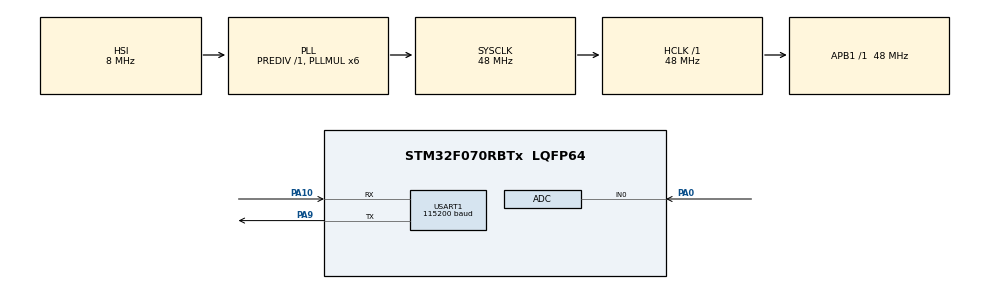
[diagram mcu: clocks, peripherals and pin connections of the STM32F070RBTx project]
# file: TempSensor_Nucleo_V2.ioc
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ADC.Resolution=ADC_RESOLUTION_10B
ADC.SamplingTime=ADC_SAMPLETIME_13CYCLES_5
Mcu.Family=STM32F0
Mcu.Name=STM32F070RBTx
Mcu.Package=LQFP64
NVIC.USART1_IRQn=true\:0\:0\:false\:false\:true\:true\:true\:true
PA0.Mode=IN0
PA0.Signal=ADC_IN0
PA10.Mode=Asynchronous
PA10.Signal=USART1_RX
PA9.Mode=Asynchronous
PA9.Signal=USART1_TX
PF0-OSC_IN.Mode=HSE-External-Oscillator
PF0-OSC_IN.Signal=RCC_OSC_IN
PF1-OSC_OUT.Mode=HSE-External-Oscillator
PF1-OSC_OUT.Signal=RCC_OSC_OUT
ProjectManager.HeapSize=0x200
ProjectManager.StackSize=0x400
ProjectManager.TargetToolchain=STM32CubeIDE
RCC.AHBFreq_Value=48000000
RCC.APB1Freq_Value=48000000
RCC.APB1TimFreq_Value=48000000
RCC.HCLKFreq_Value=48000000
RCC.PLLMUL=RCC_PLL_MUL6
RCC.SYSCLKFreq_VALUE=48000000
RCC.SYSCLKSource=RCC_SYSCLKSOURCE_PLLCLK
USART1.BaudRate=115200
USART1.VirtualMode-Asynchronous=VM_ASYNC
board=NUCLEO-F070RB

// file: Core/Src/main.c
/* USER CODE BEGIN Header */
/**
  ******************************************************************************
  * @file           : main.c
  * @brief          : Main program body
  ******************************************************************************
  * @attention
  *
  * Copyright (c) 2023 STMicroelectronics.
  * All rights reserved.
  *
  * This software is licensed under terms that can be found in the LICENSE file
  * in the root directory of this software component.
  * If no LICENSE file comes with this software, it is provided AS-IS.
  *
  ******************************************************************************
  */
/* USER CODE END Header */
#include "main.h"

/* USER CODE BEGIN Includes */ // CUSTOM CODE

#include <string.h>
#include <stdio.h>

/* USER CODE END Includes */

ADC_HandleTypeDef hadc;

UART_HandleTypeDef huart1;

void SystemClock_Config(void);
static void MX_GPIO_Init(void);
static void MX_ADC_Init(void);
static void MX_USART1_UART_Init(void);

/* USER CODE BEGIN 0 */
uint32_t adcval;
float temp;
char temp_str[20];
uint8_t msg[38] = "Hello World\n";

/* USER CODE END 0 */

int main(void)
{

  /* MCU Configuration--------------------------------------------------------*/

  /* Reset of all peripherals, Initializes the Flash interface and the Systick. */
  HAL_Init();

  /* Configure the system clock */
  SystemClock_Config();

  /* Initialize all configured peripherals */
  MX_GPIO_Init();
  MX_ADC_Init();
  MX_USART1_UART_Init();

  /* Infinite loop */
  while (1)
  {

    /* USER CODE BEGIN 3 */ // CUSTOM CODE
	  HAL_UART_Transmit(&huart1, msg, 38, 10);
	  HAL_ADC_Start(&hadc);
	  if (HAL_ADC_PollForConversion(&hadc, 5) == HAL_OK)
	  {
		  adcval = HAL_ADC_GetValue(&hadc);
		  temp = (adcval*330.0)/1023.0; // voltage = (adcval*supply_voltage) / (adc resolution)
	  	  	  	  	  	  	  	  // 10 bits adc resolution means 2^10 = 1023

		  snprintf(temp_str, sizeof(temp_str), "Temperature: %.2f C\r\n", temp); // @suppress("Float formatting support")
		  HAL_UART_Transmit(&huart1, (uint8_t *)temp_str, strlen(temp_str), HAL_MAX_DELAY);
		  HAL_Delay(1000);

	  }

  }
  /* USER CODE END 3 */
}

void SystemClock_Config(void)
{
  RCC_OscInitTypeDef RCC_OscInitStruct = {0};
  RCC_ClkInitTypeDef RCC_ClkInitStruct = {0};
  RCC_PeriphCLKInitTypeDef PeriphClkInit = {0};

  /** Initializes the RCC Oscillators according to the specified parameters
  * in the RCC_OscInitTypeDef structure.
  */
  RCC_OscInitStruct.OscillatorType = RCC_OSCILLATORTYPE_HSI|RCC_OSCILLATORTYPE_HSI14;
  RCC_OscInitStruct.HSIState = RCC_HSI_ON;
  RCC_OscInitStruct.HSI14State = RCC_HSI14_ON;
  RCC_OscInitStruct.HSICalibrationValue = RCC_HSICALIBRATION_DEFAULT;
  RCC_OscInitStruct.HSI14CalibrationValue = 16;
  RCC_OscInitStruct.PLL.PLLState = RCC_PLL_ON;
  RCC_OscInitStruct.PLL.PLLSource = RCC_PLLSOURCE_HSI;
  RCC_OscInitStruct.PLL.PLLMUL = RCC_PLL_MUL6;
  RCC_OscInitStruct.PLL.PREDIV = RCC_PREDIV_DIV1;
  if (HAL_RCC_OscConfig(&RCC_OscInitStruct) != HAL_OK)
  {
    Error_Handler();
  }

  /** Initializes the CPU, AHB and APB buses clocks
  */
  RCC_ClkInitStruct.ClockType = RCC_CLOCKTYPE_HCLK|RCC_CLOCKTYPE_SYSCLK
                              |RCC_CLOCKTYPE_PCLK1;
  RCC_ClkInitStruct.SYSCLKSource = RCC_SYSCLKSOURCE_PLLCLK;
  RCC_ClkInitStruct.AHBCLKDivider = RCC_SYSCLK_DIV1;
  RCC_ClkInitStruct.APB1CLKDivider = RCC_HCLK_DIV1;

  if (HAL_RCC_ClockConfig(&RCC_ClkInitStruct, FLASH_LATENCY_1) != HAL_OK)
  {
    Error_Handler();
  }
  PeriphClkInit.PeriphClockSelection = RCC_PERIPHCLK_USART1;
  PeriphClkInit.Usart1ClockSelection = RCC_USART1CLKSOURCE_PCLK1;
  if (HAL_RCCEx_PeriphCLKConfig(&PeriphClkInit) != HAL_OK)
  {
    Error_Handler();
  }
}

static void MX_ADC_Init(void)
{

  ADC_ChannelConfTypeDef sConfig = {0};

  /** Configure the global features of the ADC (Clock, Resolution, Data Alignment and number of conversion)
  */
  hadc.Instance = ADC1;
  hadc.Init.ClockPrescaler = ADC_CLOCK_ASYNC_DIV1;
  hadc.Init.Resolution = ADC_RESOLUTION_10B;
  hadc.Init.DataAlign = ADC_DATAALIGN_RIGHT;
  hadc.Init.ScanConvMode = ADC_SCAN_DIRECTION_FORWARD;
  hadc.Init.EOCSelection = ADC_EOC_SINGLE_CONV;
  hadc.Init.LowPowerAutoWait = DISABLE;
  hadc.Init.LowPowerAutoPowerOff = DISABLE;
  hadc.Init.ContinuousConvMode = DISABLE;
  hadc.Init.DiscontinuousConvMode = DISABLE;
  hadc.Init.ExternalTrigConv = ADC_SOFTWARE_START;
  hadc.Init.ExternalTrigConvEdge = ADC_EXTERNALTRIGCONVEDGE_NONE;
  hadc.Init.DMAContinuousRequests = DISABLE;
  hadc.Init.Overrun = ADC_OVR_DATA_PRESERVED;
  if (HAL_ADC_Init(&hadc) != HAL_OK)
  {
    Error_Handler();
  }

  /** Configure for the selected ADC regular channel to be converted.
  */
  sConfig.Channel = ADC_CHANNEL_0;
  sConfig.Rank = ADC_RANK_CHANNEL_NUMBER;
  sConfig.SamplingTime = ADC_SAMPLETIME_13CYCLES_5;
  if (HAL_ADC_ConfigChannel(&hadc, &sConfig) != HAL_OK)
  {
    Error_Handler();
  }

}

static void MX_USART1_UART_Init(void)
{

  huart1.Instance = USART1;
  huart1.Init.BaudRate = 115200;
  huart1.Init.WordLength = UART_WORDLENGTH_8B;
  huart1.Init.StopBits = UART_STOPBITS_1;
  huart1.Init.Parity = UART_PARITY_NONE;
  huart1.Init.Mode = UART_MODE_TX_RX;
  huart1.Init.HwFlowCtl = UART_HWCONTROL_NONE;
  huart1.Init.OverSampling = UART_OVERSAMPLING_16;
  huart1.Init.OneBitSampling = UART_ONE_BIT_SAMPLE_DISABLE;
  huart1.AdvancedInit.AdvFeatureInit = UART_ADVFEATURE_NO_INIT;
  if (HAL_UART_Init(&huart1) != HAL_OK)
  {
    Error_Handler();
  }

}

static void MX_GPIO_Init(void)
{

  /* GPIO Ports Clock Enable */
  __HAL_RCC_GPIOF_CLK_ENABLE();
  __HAL_RCC_GPIOA_CLK_ENABLE();

}

void Error_Handler(void)
{
  __disable_irq();
  while (1)
  {
  }
}
